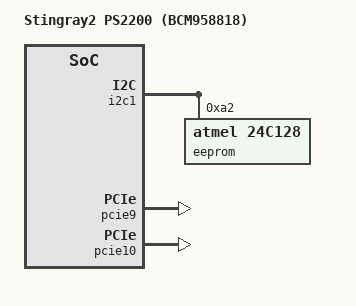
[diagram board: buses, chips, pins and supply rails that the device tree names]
// SPDX-License-Identifier: (GPL-2.0 or BSD-3-Clause)
/*
 *  Copyright(c) 2020 Broadcom
 */

/dts-v1/;

#include "stingray2-board-base.dtsi"

/ {
	model = "Stingray2 PS2200 (BCM958818)";
};

&i2c1 {
	status = "okay";
	eeprom@a2 {
		compatible = "atmel,24c128";
		reg = <0xa2>;
		pagesize = <128>;
	};
};

&pcie9 {
	status = "okay";
};

&pcie10 {
	status = "okay";
};
